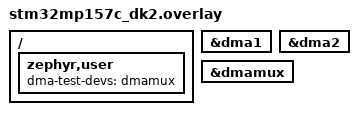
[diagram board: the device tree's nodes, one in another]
/*
 * Copyright (c) 2022 STMicroelectronics
 *
 * SPDX-License-Identifier: Apache-2.0
 */

&dma1 {
	status = "okay";
};

&dma2 {
	status = "okay";
};

&dmamux {
	status = "okay";
};

&dmamux {
	status = "okay";
};

/ {
	zephyr,user {
		dma-test-devs = <&dmamux>;
	};
};
